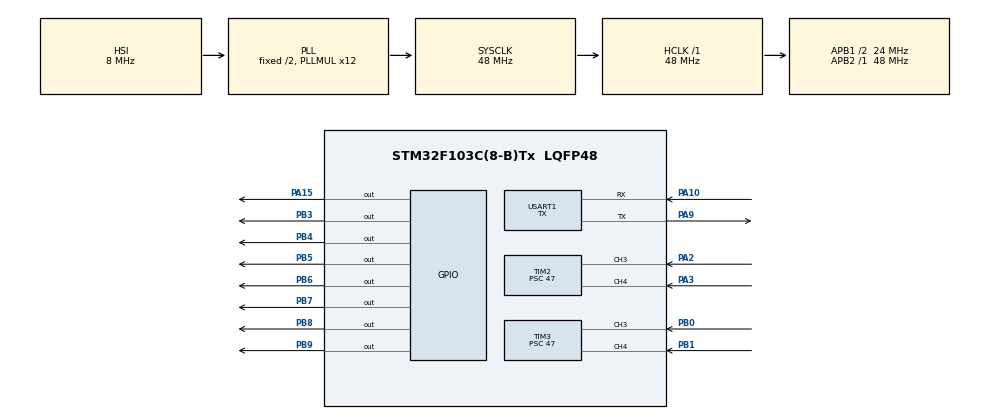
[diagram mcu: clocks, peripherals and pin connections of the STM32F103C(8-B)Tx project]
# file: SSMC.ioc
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Mcu.Family=STM32F1
Mcu.Name=STM32F103C(8-B)Tx
Mcu.Package=LQFP48
NVIC.PriorityGroup=NVIC_PRIORITYGROUP_4
NVIC.USART1_IRQn=true\:0\:0\:false\:false\:true\:true\:true
PA10.Mode=Asynchronous
PA10.Signal=USART1_RX
PA15.Signal=GPIO_Output
PA2.Signal=S_TIM2_CH3
PA3.Signal=S_TIM2_CH4
PA9.Mode=Asynchronous
PA9.Signal=USART1_TX
PB0.Signal=S_TIM3_CH3
PB1.Signal=S_TIM3_CH4
PB3.Signal=GPIO_Output
PB4.Signal=GPIO_Output
PB5.Signal=GPIO_Output
PB6.Signal=GPIO_Output
PB7.Signal=GPIO_Output
PB8.Signal=GPIO_Output
PB9.Signal=GPIO_Output
ProjectManager.HeapSize=0x200
ProjectManager.StackSize=0x400
ProjectManager.TargetToolchain=STM32CubeIDE
RCC.AHBFreq_Value=48000000
RCC.APB1CLKDivider=RCC_HCLK_DIV2
RCC.APB1Freq_Value=24000000
RCC.APB1TimFreq_Value=48000000
RCC.APB2Freq_Value=48000000
RCC.APB2TimFreq_Value=48000000
RCC.HCLKFreq_Value=48000000
RCC.PLLMUL=RCC_PLL_MUL12
RCC.SYSCLKFreq_VALUE=48000000
RCC.SYSCLKSource=RCC_SYSCLKSOURCE_PLLCLK
RCC.USBFreq_Value=48000000
SH.S_TIM2_CH3.0=TIM2_CH3,Input_Capture3_from_TI3
SH.S_TIM2_CH4.0=TIM2_CH4,Input_Capture4_from_TI4
SH.S_TIM3_CH3.0=TIM3_CH3,Input_Capture3_from_TI3
SH.S_TIM3_CH4.0=TIM3_CH4,Input_Capture4_from_TI4
TIM2.Channel-Input_Capture3_from_TI3=TIM_CHANNEL_3
TIM2.Channel-Input_Capture4_from_TI4=TIM_CHANNEL_4
TIM2.Period=0xFFFF
TIM2.Prescaler=47
TIM3.Channel-Input_Capture3_from_TI3=TIM_CHANNEL_3
TIM3.Channel-Input_Capture4_from_TI4=TIM_CHANNEL_4
TIM3.Period=0xFFFF
TIM3.Prescaler=47
USART1.Mode=MODE_TX
USART1.VirtualMode=VM_ASYNC
VP_SYS_VS_ND.Mode=No_Debug
VP_TIM2_VS_ClockSourceINT.Mode=Internal
VP_TIM3_VS_ClockSourceINT.Mode=Internal
board=custom

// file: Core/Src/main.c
/* USER CODE BEGIN Header */
/**
  ******************************************************************************
  * @file           : main.c
  * @brief          : Main program body
  ******************************************************************************
  * @attention
  *
  * <h2><center>&copy; Copyright (c) 2020 STMicroelectronics.
  * All rights reserved.</center></h2>
  *
  * This software component is licensed by ST under BSD 3-Clause license,
  * the "License"; You may not use this file except in compliance with the
  * License. You may obtain a copy of the License at:
  *                        opensource.org/licenses/BSD-3-Clause
  *
  ******************************************************************************
  */
/* USER CODE END Header */

#include "main.h"
#include "tim.h"
#include "usart.h"
#include "gpio.h"

/* USER CODE BEGIN Includes */
#include "Framework/Scheduler/scheduler.h"
#include "Framework/Common/types.h"
/* USER CODE END Includes */

void SystemClock_Config(void);

int main(void)
{

  /* MCU Configuration--------------------------------------------------------*/

  /* Reset of all peripherals, Initializes the Flash interface and the Systick. */
  HAL_Init();

  /* Configure the system clock */
  SystemClock_Config();

  /* Initialize all configured peripherals */
  MX_GPIO_Init();
  MX_TIM2_Init();
  MX_TIM3_Init();
  MX_USART1_UART_Init();

  /* Infinite loop */
  /* USER CODE BEGIN WHILE */

  scheduler_init();
  scheduler_main();

  while (1)
  {
    /* USER CODE END WHILE */

  }
}

void SystemClock_Config(void)
{
  RCC_OscInitTypeDef RCC_OscInitStruct = {0};
  RCC_ClkInitTypeDef RCC_ClkInitStruct = {0};

  /** Initializes the CPU, AHB and APB busses clocks
  */
  RCC_OscInitStruct.OscillatorType = RCC_OSCILLATORTYPE_HSI;
  RCC_OscInitStruct.HSIState = RCC_HSI_ON;
  RCC_OscInitStruct.HSICalibrationValue = RCC_HSICALIBRATION_DEFAULT;
  RCC_OscInitStruct.PLL.PLLState = RCC_PLL_ON;
  RCC_OscInitStruct.PLL.PLLSource = RCC_PLLSOURCE_HSI_DIV2;
  RCC_OscInitStruct.PLL.PLLMUL = RCC_PLL_MUL12;
  if (HAL_RCC_OscConfig(&RCC_OscInitStruct) != HAL_OK)
  {
    Error_Handler();
  }
  /** Initializes the CPU, AHB and APB busses clocks
  */
  RCC_ClkInitStruct.ClockType = RCC_CLOCKTYPE_HCLK|RCC_CLOCKTYPE_SYSCLK
                              |RCC_CLOCKTYPE_PCLK1|RCC_CLOCKTYPE_PCLK2;
  RCC_ClkInitStruct.SYSCLKSource = RCC_SYSCLKSOURCE_PLLCLK;
  RCC_ClkInitStruct.AHBCLKDivider = RCC_SYSCLK_DIV1;
  RCC_ClkInitStruct.APB1CLKDivider = RCC_HCLK_DIV2;
  RCC_ClkInitStruct.APB2CLKDivider = RCC_HCLK_DIV1;

  if (HAL_RCC_ClockConfig(&RCC_ClkInitStruct, FLASH_LATENCY_1) != HAL_OK)
  {
    Error_Handler();
  }
}

void Error_Handler(void)
{
}

/************************ (C) COPYRIGHT STMicroelectronics *****END OF FILE****/
